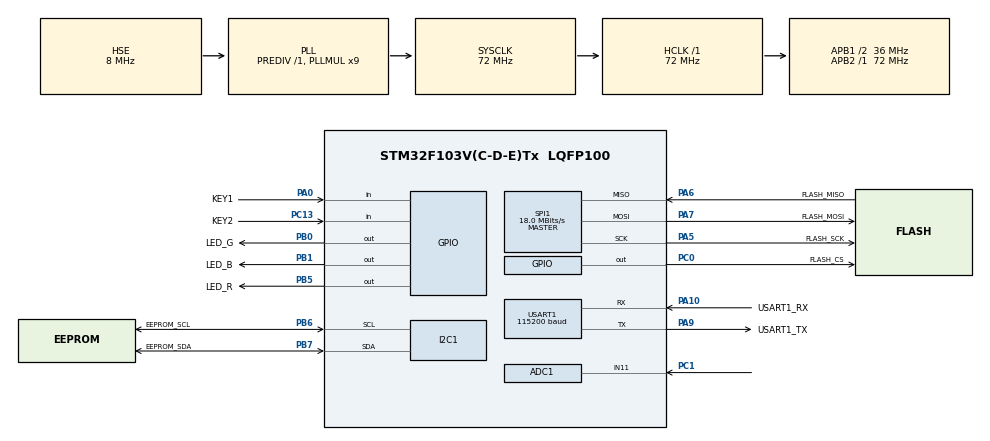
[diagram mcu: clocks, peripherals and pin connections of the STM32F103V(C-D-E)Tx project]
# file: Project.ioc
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ADC1.Channel-0\#ChannelRegularConversion=ADC_CHANNEL_11
ADC1.NbrOfConversion=1
ADC1.NbrOfConversionFlag=1
ADC1.Rank-0\#ChannelRegularConversion=1
ADC1.SamplingTime-0\#ChannelRegularConversion=ADC_SAMPLETIME_1CYCLE_5
ADC1.master=1
Dma.Request0=USART1_TX
Dma.USART1_TX.0.Direction=DMA_MEMORY_TO_PERIPH
Dma.USART1_TX.0.Instance=DMA1_Channel4
Dma.USART1_TX.0.MemDataAlignment=DMA_MDATAALIGN_HALFWORD
Dma.USART1_TX.0.MemInc=DMA_MINC_ENABLE
Dma.USART1_TX.0.Mode=DMA_NORMAL
Dma.USART1_TX.0.PeriphDataAlignment=DMA_PDATAALIGN_HALFWORD
Dma.USART1_TX.0.PeriphInc=DMA_PINC_DISABLE
Dma.USART1_TX.0.Priority=DMA_PRIORITY_LOW
FREERTOS.BinarySemaphores01=myBinarySem01,Dynamic,NULL
FREERTOS.CountingSemaphores01=myCountingSem01,16,Dynamic,NULL
FREERTOS.Mutexes01=myMutex01,Dynamic,NULL
FREERTOS.Queues01=myQueue01,16,uint16_t,0,Dynamic,NULL,NULL
FREERTOS.Tasks01=defaultTask,24,128,StartDefaultTask,Default,NULL,Dynamic,NULL,NULL;Usart_Task,8,128,Usart_Task_Function,Default,NULL,Dynamic,NULL,NULL;LED_Task,8,128,LED_Task_Function,Default,NULL,Dynamic,NULL,NULL
FREERTOS.configTOTAL_HEAP_SIZE=3072
I2C1.I2C_Mode=I2C_Fast
I2C1.NoStretchMode=I2C_NOSTRETCH_DISABLE
I2C1.OwnAddress=0x52
Mcu.Family=STM32F1
Mcu.Name=STM32F103V(C-D-E)Tx
Mcu.Package=LQFP100
NVIC.DMA1_Channel4_IRQn=true\:5\:0\:false\:false\:true\:true\:false\:true\:true
NVIC.PriorityGroup=NVIC_PRIORITYGROUP_4
NVIC.TIM6_IRQn=true\:15\:0\:false\:false\:true\:false\:false\:true\:true
NVIC.TimeBase=TIM6_IRQn
NVIC.TimeBaseIP=TIM6
NVIC.USART1_IRQn=true\:10\:0\:true\:false\:true\:true\:true\:true\:true
OSC_IN.Mode=HSE-External-Oscillator
OSC_IN.Signal=RCC_OSC_IN
OSC_OUT.Mode=HSE-External-Oscillator
OSC_OUT.Signal=RCC_OSC_OUT
PA0-WKUP.GPIO_Label=KEY1
PA0-WKUP.Signal=GPIO_Input
PA10.GPIO_Label=USART1_RX
PA10.Mode=Asynchronous
PA10.Signal=USART1_RX
PA13.Mode=Serial_Wire
PA13.Signal=SYS_JTMS-SWDIO
PA14.Mode=Serial_Wire
PA14.Signal=SYS_JTCK-SWCLK
PA5.GPIO_Label=FLASH_SCK
PA5.Mode=Full_Duplex_Master
PA5.Signal=SPI1_SCK
PA6.GPIO_Label=FLASH_MISO
PA6.Mode=Full_Duplex_Master
PA6.Signal=SPI1_MISO
PA7.GPIO_Label=FLASH_MOSI
PA7.Mode=Full_Duplex_Master
PA7.Signal=SPI1_MOSI
PA9.GPIO_Label=USART1_TX
PA9.Mode=Asynchronous
PA9.Signal=USART1_TX
PB0.GPIO_Label=LED_G
PB0.PinState=GPIO_PIN_SET
PB0.Signal=GPIO_Output
PB1.GPIO_Label=LED_B
PB1.PinState=GPIO_PIN_SET
PB1.Signal=GPIO_Output
PB5.GPIO_Label=LED_R
PB5.PinState=GPIO_PIN_SET
PB5.Signal=GPIO_Output
PB6.GPIO_Label=EEPROM_SCL
PB6.Mode=I2C
PB6.Signal=I2C1_SCL
PB7.GPIO_Label=EEPROM_SDA
PB7.Mode=I2C
PB7.Signal=I2C1_SDA
PC0.GPIO_Label=FLASH_CS
PC0.GPIO_Speed=GPIO_SPEED_FREQ_HIGH
PC0.PinState=GPIO_PIN_SET
PC0.Signal=GPIO_Output
PC1.Signal=ADCx_IN11
PC13-TAMPER-RTC.GPIO_Label=KEY2
PC13-TAMPER-RTC.Signal=GPIO_Input
PC14-OSC32_IN.Mode=LSE-External-Oscillator
PC14-OSC32_IN.Signal=RCC_OSC32_IN
PC15-OSC32_OUT.Mode=LSE-External-Oscillator
PC15-OSC32_OUT.Signal=RCC_OSC32_OUT
ProjectManager.HeapSize=0x200
ProjectManager.StackSize=0x400
ProjectManager.TargetToolchain=MDK-ARM V5.27
RCC.ADCPresc=RCC_ADCPCLK2_DIV6
RCC.AHBFreq_Value=72000000
RCC.APB1CLKDivider=RCC_HCLK_DIV2
RCC.APB1Freq_Value=36000000
RCC.APB1TimFreq_Value=72000000
RCC.APB2Freq_Value=72000000
RCC.APB2TimFreq_Value=72000000
RCC.HCLKFreq_Value=72000000
RCC.PLLMUL=RCC_PLL_MUL9
RCC.PLLSourceVirtual=RCC_PLLSOURCE_HSE
RCC.SYSCLKFreq_VALUE=72000000
RCC.SYSCLKSource=RCC_SYSCLKSOURCE_PLLCLK
RCC.USBFreq_Value=72000000
SH.ADCx_IN11.0=ADC1_IN11,IN11
SPI1.BaudRatePrescaler=SPI_BAUDRATEPRESCALER_4
SPI1.CLKPhase=SPI_PHASE_1EDGE
SPI1.CLKPolarity=SPI_POLARITY_LOW
SPI1.CalculateBaudRate=18.0 MBits/s
SPI1.Direction=SPI_DIRECTION_2LINES
SPI1.Mode=SPI_MODE_MASTER
SPI1.VirtualType=VM_MASTER
USART1.BaudRate=115200
USART1.VirtualMode=VM_ASYNC
VP_FREERTOS_VS_CMSIS_V2.Mode=CMSIS_V2
VP_SYS_VS_tim6.Mode=TIM6
board=custom

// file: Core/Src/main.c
/* USER CODE BEGIN Header */
/**
 ******************************************************************************
 * @file           : main.c
 * @brief          : Main program body
 ******************************************************************************
 * @attention
 *
 * Copyright (c) 2024 STMicroelectronics.
 * All rights reserved.
 *
 * This software is licensed under terms that can be found in the LICENSE file
 * in the root directory of this software component.
 * If no LICENSE file comes with this software, it is provided AS-IS.
 *
 ******************************************************************************
 */
/* USER CODE END Header */
#include "main.h"
#include "cmsis_os.h"
#include "adc.h"
#include "dma.h"
#include "i2c.h"
#include "spi.h"
#include "usart.h"
#include "gpio.h"

void SystemClock_Config(void);
void MX_FREERTOS_Init(void);

int main(void)
{

  /* MCU Configuration--------------------------------------------------------*/

  /* Reset of all peripherals, Initializes the Flash interface and the Systick. */
  HAL_Init();

  /* Configure the system clock */
  SystemClock_Config();

  /* Initialize all configured peripherals */
  MX_GPIO_Init();
  MX_DMA_Init();
  MX_USART1_UART_Init();
  MX_I2C1_Init();
  MX_SPI1_Init();
  MX_ADC1_Init();

  /* Init scheduler */
  osKernelInitialize();

  /* Call init function for freertos objects (in cmsis_os2.c) */
  MX_FREERTOS_Init();

  /* Start scheduler */
  osKernelStart();

  /* We should never get here as control is now taken by the scheduler */

  /* Infinite loop */
	while (1)
	{

	}
}

void SystemClock_Config(void)
{
  RCC_OscInitTypeDef RCC_OscInitStruct = {0};
  RCC_ClkInitTypeDef RCC_ClkInitStruct = {0};
  RCC_PeriphCLKInitTypeDef PeriphClkInit = {0};

  /** Initializes the RCC Oscillators according to the specified parameters
  * in the RCC_OscInitTypeDef structure.
  */
  RCC_OscInitStruct.OscillatorType = RCC_OSCILLATORTYPE_HSE;
  RCC_OscInitStruct.HSEState = RCC_HSE_ON;
  RCC_OscInitStruct.HSEPredivValue = RCC_HSE_PREDIV_DIV1;
  RCC_OscInitStruct.HSIState = RCC_HSI_ON;
  RCC_OscInitStruct.PLL.PLLState = RCC_PLL_ON;
  RCC_OscInitStruct.PLL.PLLSource = RCC_PLLSOURCE_HSE;
  RCC_OscInitStruct.PLL.PLLMUL = RCC_PLL_MUL9;
  if (HAL_RCC_OscConfig(&RCC_OscInitStruct) != HAL_OK)
  {
    Error_Handler();
  }

  /** Initializes the CPU, AHB and APB buses clocks
  */
  RCC_ClkInitStruct.ClockType = RCC_CLOCKTYPE_HCLK|RCC_CLOCKTYPE_SYSCLK
                              |RCC_CLOCKTYPE_PCLK1|RCC_CLOCKTYPE_PCLK2;
  RCC_ClkInitStruct.SYSCLKSource = RCC_SYSCLKSOURCE_PLLCLK;
  RCC_ClkInitStruct.AHBCLKDivider = RCC_SYSCLK_DIV1;
  RCC_ClkInitStruct.APB1CLKDivider = RCC_HCLK_DIV2;
  RCC_ClkInitStruct.APB2CLKDivider = RCC_HCLK_DIV1;

  if (HAL_RCC_ClockConfig(&RCC_ClkInitStruct, FLASH_LATENCY_2) != HAL_OK)
  {
    Error_Handler();
  }
  PeriphClkInit.PeriphClockSelection = RCC_PERIPHCLK_ADC;
  PeriphClkInit.AdcClockSelection = RCC_ADCPCLK2_DIV6;
  if (HAL_RCCEx_PeriphCLKConfig(&PeriphClkInit) != HAL_OK)
  {
    Error_Handler();
  }
}

void HAL_TIM_PeriodElapsedCallback(TIM_HandleTypeDef *htim)
{
  if (htim->Instance == TIM6) {
    HAL_IncTick();
  }
}

void Error_Handler(void)
{
	__disable_irq();
	while (1)
	{
	}
}

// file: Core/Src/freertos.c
/* USER CODE BEGIN Header */
/**
  ******************************************************************************
  * File Name          : freertos.c
  * Description        : Code for freertos applications
  ******************************************************************************
  * @attention
  *
  * Copyright (c) 2024 STMicroelectronics.
  * All rights reserved.
  *
  * This software is licensed under terms that can be found in the LICENSE file
  * in the root directory of this software component.
  * If no LICENSE file comes with this software, it is provided AS-IS.
  *
  ******************************************************************************
  */
/* USER CODE END Header */

#include "FreeRTOS.h"
#include "task.h"
#include "main.h"
#include "cmsis_os.h"

/* Definitions for defaultTask */
osThreadId_t defaultTaskHandle;
const osThreadAttr_t defaultTask_attributes = {
  .name = "defaultTask",
  .stack_size = 128 * 4,
  .priority = (osPriority_t) osPriorityNormal,
};
/* Definitions for Usart_Task */
osThreadId_t Usart_TaskHandle;
const osThreadAttr_t Usart_Task_attributes = {
  .name = "Usart_Task",
  .stack_size = 128 * 4,
  .priority = (osPriority_t) osPriorityLow,
};
/* Definitions for LED_Task */
osThreadId_t LED_TaskHandle;
const osThreadAttr_t LED_Task_attributes = {
  .name = "LED_Task",
  .stack_size = 128 * 4,
  .priority = (osPriority_t) osPriorityLow,
};
/* Definitions for myQueue01 */
osMessageQueueId_t myQueue01Handle;
const osMessageQueueAttr_t myQueue01_attributes = {
  .name = "myQueue01"
};
/* Definitions for myMutex01 */
osMutexId_t myMutex01Handle;
const osMutexAttr_t myMutex01_attributes = {
  .name = "myMutex01"
};
/* Definitions for myBinarySem01 */
osSemaphoreId_t myBinarySem01Handle;
const osSemaphoreAttr_t myBinarySem01_attributes = {
  .name = "myBinarySem01"
};
/* Definitions for myCountingSem01 */
osSemaphoreId_t myCountingSem01Handle;
const osSemaphoreAttr_t myCountingSem01_attributes = {
  .name = "myCountingSem01"
};

void StartDefaultTask(void *argument);
void Usart_Task_Function(void *argument);
void LED_Task_Function(void *argument);

void MX_FREERTOS_Init(void); /* (MISRA C 2004 rule 8.1) */

void MX_FREERTOS_Init(void) {
  /* Create the mutex(es) */
  /* creation of myMutex01 */
  myMutex01Handle = osMutexNew(&myMutex01_attributes);

  /* Create the semaphores(s) */
  /* creation of myBinarySem01 */
  myBinarySem01Handle = osSemaphoreNew(1, 0, &myBinarySem01_attributes);

  /* creation of myCountingSem01 */
  myCountingSem01Handle = osSemaphoreNew(16, 16, &myCountingSem01_attributes);

  /* Create the queue(s) */
  /* creation of myQueue01 */
  myQueue01Handle = osMessageQueueNew (16, sizeof(uint16_t), &myQueue01_attributes);

  /* Create the thread(s) */
  /* creation of defaultTask */
  defaultTaskHandle = osThreadNew(StartDefaultTask, NULL, &defaultTask_attributes);

  /* creation of Usart_Task */
  Usart_TaskHandle = osThreadNew(Usart_Task_Function, NULL, &Usart_Task_attributes);

  /* creation of LED_Task */
  LED_TaskHandle = osThreadNew(LED_Task_Function, NULL, &LED_Task_attributes);

}

void StartDefaultTask(void *argument)
{
  for(;;)
  {
    osDelay(1);
  }
}

void Usart_Task_Function(void *argument)
{
  /* USER CODE BEGIN Usart_Task_Function */

	HAL_UART_Receive_IT(&huart1, rx_data, 1);
//  HAL_UART_Transmit_DMA(&huart1,(const uint8_t*)0x08036800,256);

  /* Infinite loop */
  for(;;)
  {
	printf("xTaskGetTickCount:%.4d\r\n",xTaskGetTickCount());
    osDelay(1000);
  }
  /* USER CODE END Usart_Task_Function */
}

void LED_Task_Function(void *argument)
{
  /* USER CODE BEGIN LED_Task_Function */
  /* Infinite loop */
  for(;;)
  {
	LED_Colour_Ctrl(LED_Colour_red );
    osDelay(1000);
	LED_Colour_Ctrl(LED_Colour_black);
    osDelay(1000);
}
  /* USER CODE END LED_Task_Function */
}
